# ESP32-S2 register map
Vendor: ESPRESSIF SYSTEMS (SHANGHAI) CO., LTD.; Series: ESP32 S-Series; File version: 20
CPU: Xtensa LX7 r0p0, little endian, no MPU, no FPU, 0 interrupt priority bits
Address unit: 32 bits
Registers are 32-bit, read-write, reset 0x0 unless marked. A register's access mark holds for its fields unless they carry their own. Offsets are from the block's base; [hi:lo] are bit positions; {n}, {i} and the like mark numbered series; <NAME> marks a mode.

## APB_SARADC — SAR (Successive Approximation Register) Analog-to-Digital Converter
Base 0x3F440000
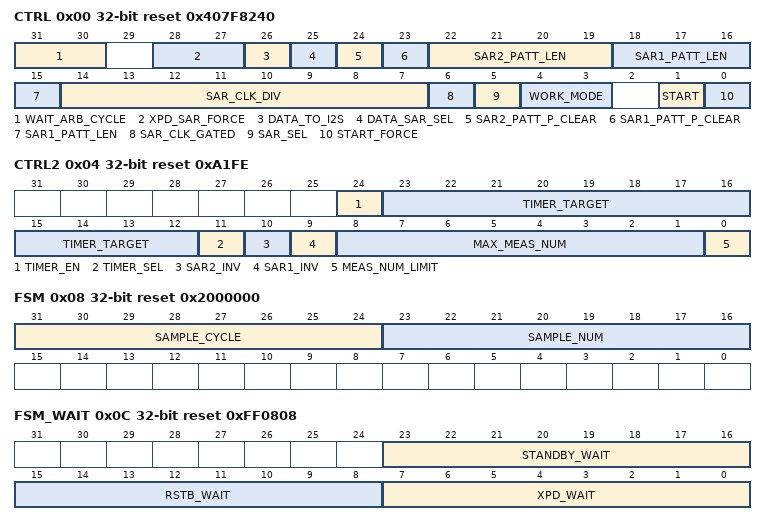
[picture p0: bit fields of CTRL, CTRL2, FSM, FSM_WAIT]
0x00 CTRL reset 0x407F8240 — DIG ADC common configuration
  [31:30] WAIT_ARB_CYCLE — Wait arbit signal stable after sar_done.
  [28:27] XPD_SAR_FORCE — Force option to xpd sar blocks.
  [26] DATA_TO_I2S — 1: I2S input data is from SAR ADC (for DMA), 0: I2S input data is from GPIO matrix
  [25] DATA_SAR_SEL — 1: sar_sel will be coded to the MSB of the 16-bit output data, in this case the resolution should not be larger than 11 bits.
  [24] SAR2_PATT_P_CLEAR — Clear the pointer of pattern table for DIG ADC2 CTRL.
  [23] SAR1_PATT_P_CLEAR — Clear the pointer of pattern table for DIG ADC1 CTRL.
  [22:19] SAR2_PATT_LEN — 0 ~ 15 means length 1 ~ 16
  [18:15] SAR1_PATT_LEN — 0 ~ 15 means length 1 ~ 16
  [14:7] SAR_CLK_DIV — SAR clock divider
  [6] SAR_CLK_GATED — SAR clock gate enable bit.
  [5] SAR_SEL — 0: select SAR ADC1. 1: select SAR ADC2, only work for single-channel scan mode.
  [4:3] WORK_MODE — 0: single-channel scan mode. 1: double-channel scan mode. 2: alternate-channel scan mode.
  [1] START — Start SAR ADC by software.
  [0] START_FORCE — 0: select FSM to start SAR ADC. 1: select software to start SAR ADC.
0x04 CTRL2 reset 0xA1FE — DIG ADC common configuration
  [24] TIMER_EN — Enable SAR ADC timer trigger.
  [23:12] TIMER_TARGET — Set SAR ADC timer target.
  [11] TIMER_SEL — 1: select saradc timer 0: i2s_ws trigger
  [10] SAR2_INV — 1: data to DIG ADC2 CTRL is inverted, otherwise not.
  [9] SAR1_INV — 1: data to DIG ADC1 CTRL is inverted, otherwise not.
  [8:1] MAX_MEAS_NUM — Set maximum conversion number.
  [0] MEAS_NUM_LIMIT — Enable limit times of SAR ADC sample.
0x08 FSM reset 0x2000000 — digital adc control register
  [31:24] SAMPLE_CYCLE — sample cycles
  [23:16] SAMPLE_NUM — sample number
0x0C FSM_WAIT reset 0xFF0808 — configure saradc fsm internal parameter base on test
  [23:16] STANDBY_WAIT
  [15:8] RSTB_WAIT — reset time
  [7:0] XPD_WAIT
0x10 SAR1_STATUS ro — digital adc1 status
0x14 SAR2_STATUS ro — digital adc2 status
0x18 SAR1_PATT_TAB1 reset 0xF0F0F0F — item 0 ~ 3 for pattern table 1 (each item one byte)
{0x14+4i} SAR1_PATT_TAB{i} reset 0xF0F0F0F (i=2..4) — Item {4i-4} ~ {4i-1} for pattern table 1 (each item one byte)
0x28 SAR2_PATT_TAB1 reset 0xF0F0F0F — item 0 ~ 3 for pattern table 2 (each item one byte)
{0x24+4i} SAR2_PATT_TAB{i} reset 0xF0F0F0F (i=2..4) — Item {4i-4} ~ {4i-1} for pattern table 2 (each item one byte)
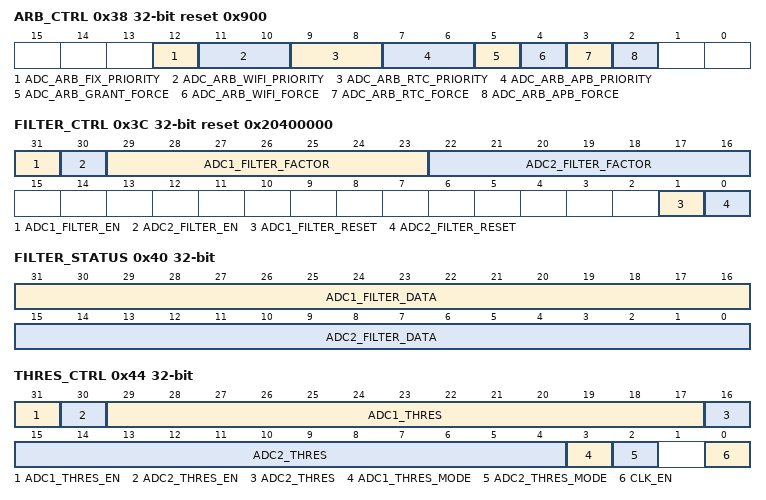
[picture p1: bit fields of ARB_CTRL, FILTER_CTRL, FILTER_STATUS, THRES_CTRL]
0x38 ARB_CTRL reset 0x900 — Configure the settings of DIG ADC2 arbiter
  [12] ADC_ARB_FIX_PRIORITY — ADC2 arbiter uses fixed priority.
  [11:10] ADC_ARB_WIFI_PRIORITY — Set PWDET/PKDET CTRL priority.
  [9:8] ADC_ARB_RTC_PRIORITY — Set RTC ADC2 CTRL priority.
  [7:6] ADC_ARB_APB_PRIORITY — Set DIG ADC2 CTRL priority.
  [5] ADC_ARB_GRANT_FORCE — ADC2 arbiter force grant.
  [4] ADC_ARB_WIFI_FORCE — ADC2 arbiter forces to enable PWDET/PKDET CTRL.
  [3] ADC_ARB_RTC_FORCE — ADC2 arbiter forces to enable RTC ADC2 CTRL.
  [2] ADC_ARB_APB_FORCE — ADC2 arbiter forces to enable DIG ADC2 CTRL.
0x3C FILTER_CTRL reset 0x20400000 — Configure the settings of DIG ADC2 filter
  [31] ADC1_FILTER_EN — Enable DIG ADC1 CRTL filter.
  [30] ADC2_FILTER_EN — Enable DIG ADC2 CRTL filter.
  [29:23] ADC1_FILTER_FACTOR — Set filter factor for DIG ADC1 CRTL.
  [22:16] ADC2_FILTER_FACTOR — Set filter factor for DIG ADC2 CRTL.
  [1] ADC1_FILTER_RESET — Reset ADC1 filter.
  [0] ADC2_FILTER_RESET — Reset ADC2 filter.
0x40 FILTER_STATUS ro — Data status of DIG ADC2 filter
  [31:16] ADC1_FILTER_DATA, [15:0] ADC2_FILTER_DATA
0x44 THRES_CTRL — Configure monitor threshold for DIG ADC2
  [31] ADC1_THRES_EN — Enable ADC1 threshold monitor.
  [30] ADC2_THRES_EN — Enable ADC2 threshold monitor.
  [29:17] ADC1_THRES — ADC1 threshold.
  [16:4] ADC2_THRES — ADC2 threshold.
  [3] ADC1_THRES_MODE — 1: ADC_DATA > = threshold, generate interrupt. 0: ADC_DATA < threshold, generate interrupt.
  [2] ADC2_THRES_MODE — 1: ADC_DATA > = threshold, generate interrupt. 0: ADC_DATA < threshold, generate interrupt.
  [0] CLK_EN — Clock gate enable.
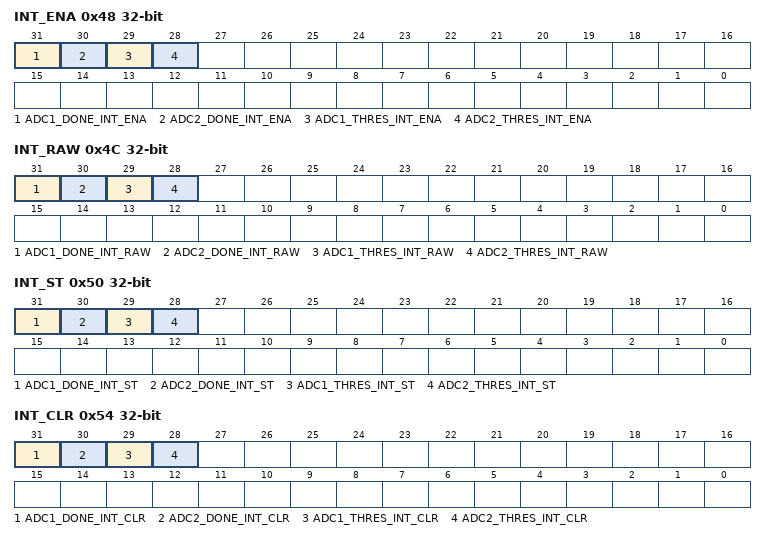
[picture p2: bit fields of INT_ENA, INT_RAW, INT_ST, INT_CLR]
0x48 INT_ENA — Enable DIG ADC interrupts
  [31] ADC1_DONE_INT_ENA — Enable bit of APB_SARADC_ADC1_DONE_INT interrupt.
  [30] ADC2_DONE_INT_ENA — Enable bit of APB_SARADC_ADC2_DONE_INT interrupt.
  [29] ADC1_THRES_INT_ENA — Enable bit of APB_SARADC_ADC1_THRES_INT interrupt.
  [28] ADC2_THRES_INT_ENA — Enable bit of APB_SARADC_ADC2_THRES_INT interrupt.
0x4C INT_RAW ro — DIG ADC interrupt raw bits
  [31] ADC1_DONE_INT_RAW — Raw bit of APB_SARADC_ADC1_DONE_INT interrupt.
  [30] ADC2_DONE_INT_RAW — Raw bit of APB_SARADC_ADC2_DONE_INT interrupt.
  [29] ADC1_THRES_INT_RAW — Raw bit of APB_SARADC_ADC1_THRES_INT interrupt.
  [28] ADC2_THRES_INT_RAW — Raw bit of APB_SARADC_ADC2_THRES_INT interrupt.
0x50 INT_ST ro — DIG ADC interrupt status
  [31] ADC1_DONE_INT_ST — Status of APB_SARADC_ADC1_DONE_INT interrupt.
  [30] ADC2_DONE_INT_ST — Status of APB_SARADC_ADC2_DONE_INT interrupt.
  [29] ADC1_THRES_INT_ST — Status of APB_SARADC_ADC1_THRES_INT interrupt.
  [28] ADC2_THRES_INT_ST — Status of APB_SARADC_ADC2_THRES_INT interrupt.
0x54 INT_CLR wo — Clear DIG ADC interrupts
  [31] ADC1_DONE_INT_CLR — Clear bit of APB_SARADC_ADC1_DONE_INT interrupt.
  [30] ADC2_DONE_INT_CLR — Clear bit of APB_SARADC_ADC2_DONE_INT interrupt.
  [29] ADC1_THRES_INT_CLR — Clear bit of APB_SARADC_ADC1_THRES_INT interrupt.
  [28] ADC2_THRES_INT_CLR — Clear bit of APB_SARADC_ADC2_THRES_INT interrupt.
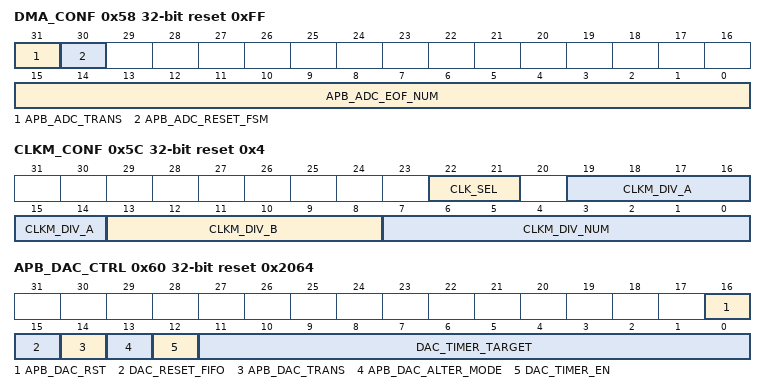
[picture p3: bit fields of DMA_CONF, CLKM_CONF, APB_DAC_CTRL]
0x58 DMA_CONF reset 0xFF — Configure digital ADC DMA path
  [31] APB_ADC_TRANS — Set this bit, DIG ADC CTRL uses SPI DMA.
  [30] APB_ADC_RESET_FSM — Reset DIG ADC CTRL status.
  [15:0] APB_ADC_EOF_NUM — Generate dma_in_suc_eof when sample cnt = spi_eof_num.
0x5C CLKM_CONF reset 0x4 — Configure DIG ADC clock
  [22:21] CLK_SEL — 1: select APLL. 2: select APB_CLK. Other values: disable clock.
  [19:14] CLKM_DIV_A — Fractional clock divider denominator value
  [13:8] CLKM_DIV_B — Fractional clock divider numerator value
  [7:0] CLKM_DIV_NUM — Integral DIG_ADC clock divider value
0x60 APB_DAC_CTRL reset 0x2064 — Configure DAC settings
  [16] APB_DAC_RST — Reset DIG DAC by software.
  [15] DAC_RESET_FIFO — Reset DIG DAC FIFO.
  [14] APB_DAC_TRANS — Enable DMA_DAC.
  [13] APB_DAC_ALTER_MODE — Enable DAC alter mode.
  [12] DAC_TIMER_EN — Enable read dac data.
  [11:0] DAC_TIMER_TARGET — Set DAC timer target.
0x3FC APB_CTRL_DATE reset 0x1907162 — Version control register
